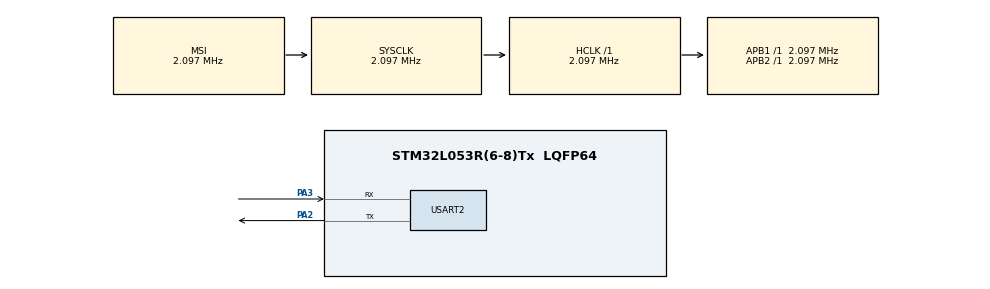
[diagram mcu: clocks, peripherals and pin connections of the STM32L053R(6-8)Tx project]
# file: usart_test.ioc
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Dma.Request0=USART2_RX
Dma.USART2_RX.0.Direction=DMA_PERIPH_TO_MEMORY
Dma.USART2_RX.0.Instance=DMA1_Channel5
Dma.USART2_RX.0.MemDataAlignment=DMA_MDATAALIGN_BYTE
Dma.USART2_RX.0.MemInc=DMA_MINC_ENABLE
Dma.USART2_RX.0.Mode=DMA_CIRCULAR
Dma.USART2_RX.0.PeriphDataAlignment=DMA_PDATAALIGN_BYTE
Dma.USART2_RX.0.PeriphInc=DMA_PINC_DISABLE
Dma.USART2_RX.0.Priority=DMA_PRIORITY_LOW
Mcu.Family=STM32L0
Mcu.Name=STM32L053R(6-8)Tx
Mcu.Package=LQFP64
NVIC.DMA1_Channel4_5_6_7_IRQn=true\:0\:0\:false\:false\:true\:false\:true\:true
NVIC.USART2_IRQn=true\:0\:0\:false\:false\:true\:true\:true\:true
PA2.Mode=Asynchronous
PA2.Signal=USART2_TX
PA3.Mode=Asynchronous
PA3.Signal=USART2_RX
ProjectManager.HeapSize=0x200
ProjectManager.StackSize=0x400
ProjectManager.TargetToolchain=MDK-ARM V5.32
RCC.AHBFreq_Value=2097000
RCC.APB1Freq_Value=2097000
RCC.APB1TimFreq_Value=2097000
RCC.APB2Freq_Value=2097000
RCC.APB2TimFreq_Value=2097000
RCC.HSE_VALUE=8000000
RCC.HSI16_VALUE=16000000
RCC.HSI48_VALUE=48000000
RCC.HSI_VALUE=16000000
RCC.MSI_VALUE=2097000
RCC.SYSCLKFreq_VALUE=2097000
RCC.VCOOutputFreq_Value=48000000
USART2.VirtualMode-Asynchronous=VM_ASYNC
board=NUCLEO-L053R8

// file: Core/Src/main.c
/* USER CODE BEGIN Header */
/**
  ******************************************************************************
  * @file           : main.c
  * @brief          : Main program body
  ******************************************************************************
  * @attention
  *
  * Copyright (c) 2023 STMicroelectronics.
  * All rights reserved.
  *
  * This software is licensed under terms that can be found in the LICENSE file
  * in the root directory of this software component.
  * If no LICENSE file comes with this software, it is provided AS-IS.
  *
  ******************************************************************************
  */
/* USER CODE END Header */
#include "main.h"
#include "dma.h"
#include "usart.h"
#include "gpio.h"

void SystemClock_Config(void);

/* USER CODE BEGIN 0 */
uint8_t myTxData[13] = "Hello world\r\n";
uint8_t myRxData[11];
/* USER CODE END 0 */

int main(void)
{

  /* MCU Configuration--------------------------------------------------------*/

  /* Reset of all peripherals, Initializes the Flash interface and the Systick. */
  HAL_Init();

  /* Configure the system clock */
  SystemClock_Config();

  /* Initialize all configured peripherals */
  MX_GPIO_Init();
  MX_DMA_Init();
  MX_USART2_UART_Init();
  /* USER CODE BEGIN 2 */
	HAL_UART_Receive_DMA(&huart2,myRxData,11);
  /* USER CODE END 2 */

  /* Infinite loop */
  while (1)
  {

    /* USER CODE BEGIN 3 */
		//HAL_UART_Transmit(&huart2, myTxData, 13 ,10);
  }
  /* USER CODE END 3 */
}

void SystemClock_Config(void)
{
  RCC_OscInitTypeDef RCC_OscInitStruct = {0};
  RCC_ClkInitTypeDef RCC_ClkInitStruct = {0};
  RCC_PeriphCLKInitTypeDef PeriphClkInit = {0};

  /** Configure the main internal regulator output voltage
  */
  __HAL_PWR_VOLTAGESCALING_CONFIG(PWR_REGULATOR_VOLTAGE_SCALE1);

  /** Initializes the RCC Oscillators according to the specified parameters
  * in the RCC_OscInitTypeDef structure.
  */
  RCC_OscInitStruct.OscillatorType = RCC_OSCILLATORTYPE_MSI;
  RCC_OscInitStruct.MSIState = RCC_MSI_ON;
  RCC_OscInitStruct.MSICalibrationValue = 0;
  RCC_OscInitStruct.MSIClockRange = RCC_MSIRANGE_5;
  RCC_OscInitStruct.PLL.PLLState = RCC_PLL_NONE;
  if (HAL_RCC_OscConfig(&RCC_OscInitStruct) != HAL_OK)
  {
    Error_Handler();
  }

  /** Initializes the CPU, AHB and APB buses clocks
  */
  RCC_ClkInitStruct.ClockType = RCC_CLOCKTYPE_HCLK|RCC_CLOCKTYPE_SYSCLK
                              |RCC_CLOCKTYPE_PCLK1|RCC_CLOCKTYPE_PCLK2;
  RCC_ClkInitStruct.SYSCLKSource = RCC_SYSCLKSOURCE_MSI;
  RCC_ClkInitStruct.AHBCLKDivider = RCC_SYSCLK_DIV1;
  RCC_ClkInitStruct.APB1CLKDivider = RCC_HCLK_DIV1;
  RCC_ClkInitStruct.APB2CLKDivider = RCC_HCLK_DIV1;

  if (HAL_RCC_ClockConfig(&RCC_ClkInitStruct, FLASH_LATENCY_0) != HAL_OK)
  {
    Error_Handler();
  }
  PeriphClkInit.PeriphClockSelection = RCC_PERIPHCLK_USART2;
  PeriphClkInit.Usart2ClockSelection = RCC_USART2CLKSOURCE_PCLK1;
  if (HAL_RCCEx_PeriphCLKConfig(&PeriphClkInit) != HAL_OK)
  {
    Error_Handler();
  }
}

/* USER CODE BEGIN 4 */
void HAL_UART_RxCpltCallback(UART_HandleTypeDef *huart)
{
  /* Prevent unused argument(s) compilation warning */
  UNUSED(huart);

  /* NOTE : This function should not be modified, when the callback is needed,
            the HAL_UART_RxCpltCallback can be implemented in the user file.
   */

	HAL_UART_Transmit(&huart2, myRxData, 11 ,10);
}
/* USER CODE END 4 */

void Error_Handler(void)
{
  __disable_irq();
  while (1)
  {
  }
}
